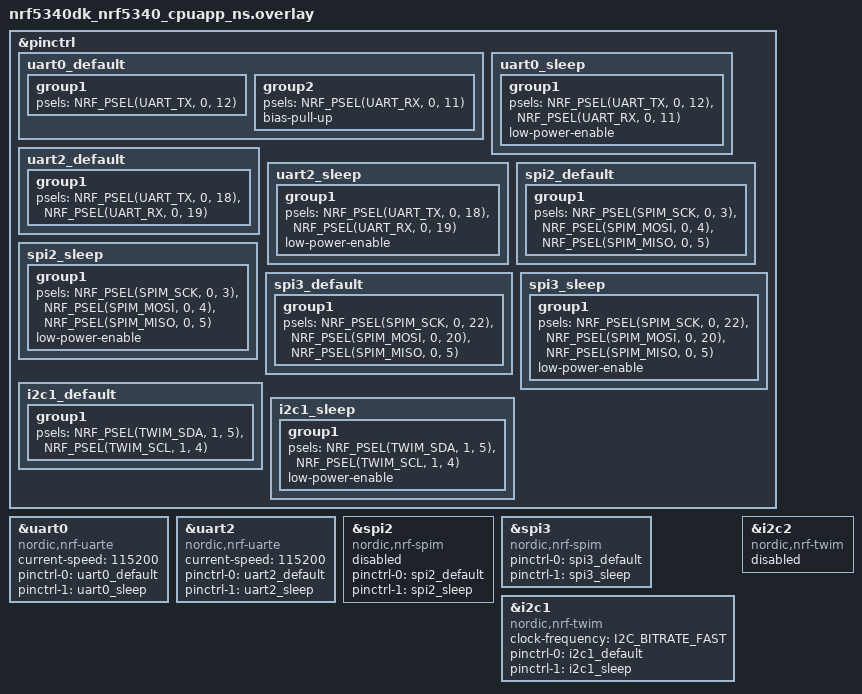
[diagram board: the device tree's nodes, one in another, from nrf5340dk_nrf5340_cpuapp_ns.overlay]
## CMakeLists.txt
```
#
# Copyright (c) 2019 Nordic Semiconductor ASA
#
# SPDX-License-Identifier: LicenseRef-BSD-5-Clause-Nordic
#

cmake_minimum_required(VERSION 3.20.0)

if (EXISTS "${CMAKE_CURRENT_SOURCE_DIR}/spm.conf")
  set(spm_CONF_FILE
    prj.conf
    ${CMAKE_CURRENT_LIST_DIR}/spm.conf
  )
endif()

if (EXISTS "${CMAKE_CURRENT_SOURCE_DIR}/mcuboot.conf")
  set(mcuboot_CONF_FILE
    prj.conf
    ${CMAKE_CURRENT_LIST_DIR}/mcuboot.conf
  )
endif()

find_package(Zephyr REQUIRED HINTS $ENV{ZEPHYR_BASE})
project(E2)
zephyr_compile_definitions(PROJECT_NAME=${PROJECT_NAME})

# NORDIC SDK APP START
target_sources(app PRIVATE src/main.c)
# NORDIC SDK APP END

# Include source directory
target_include_directories(app PRIVATE src)
target_include_directories(app PRIVATE $ENV{ZEPHYR_BASE}/subsys/fs/nvs)

# Application directories
add_subdirectory(src/datetime)
add_subdirectory(src/font)
add_subdirectory(src/image)
add_subdirectory(src/lcd)
add_subdirectory(src/key)
add_subdirectory(src/settings)
add_subdirectory(src/inner_flash)
add_subdirectory(src/external_flash)
add_subdirectory(src/uart_ble)
add_subdirectory(src/screen)
add_subdirectory(src/pmu)
add_subdirectory(src/codetrans)
add_subdirectory(src/communicate)
add_subdirectory(src/ucs2)
add_subdirectory(src/logger)

add_subdirectory_ifdef(CONFIG_PPG_SUPPORT src/ppg)
add_subdirectory_ifdef(CONFIG_WATCHDOG src/watchdog)
add_subdirectory_ifdef(CONFIG_FACTORY_TEST_SUPPORT src/factory_test)
```

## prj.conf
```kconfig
#
# Copyright (c) 2022 Nordic Semiconductor ASA
#
# SPDX-License-Identifier: LicenseRef-Nordic-5-Clause
#
# General config
CONFIG_NEWLIB_LIBC=y
CONFIG_NEWLIB_LIBC_FLOAT_PRINTF=y
CONFIG_ASSERT=y
CONFIG_REBOOT=y
CONFIG_GPIO=y
CONFIG_TRUSTED_EXECUTION_NONSECURE=y

# Log
CONFIG_LOG=y
CONFIG_USE_SEGGER_RTT=y
CONFIG_LOG_BACKEND_RTT=y
CONFIG_LOG_BACKEND_UART=n
CONFIG_LOG_DEFAULT_LEVEL=4
CONFIG_LOG_MODE_OVERFLOW=y
CONFIG_LOG_BACKEND_RTT_MODE_DROP=y
CONFIG_LOG_BACKEND_SHOW_COLOR=n
CONFIG_LOG_BACKEND_FORMAT_TIMESTAMP=n

# PinCtrl
CONFIG_PINCTRL=y
CONFIG_PINCTRL_NRF=y

# watch dog
CONFIG_WATCHDOG=y
CONFIG_WATCHDOG_TIMEOUT_MSEC=10000

# Fuel gauge
CONFIG_NRF_FUEL_GAUGE=y

# NVS
CONFIG_FLASH=y
CONFIG_FLASH_PAGE_LAYOUT=y
CONFIG_NVS=y
CONFIG_NVS_LOG_LEVEL_DBG=y
CONFIG_MPU_ALLOW_FLASH_WRITE=y

# Console
CONFIG_CONSOLE_SUBSYS=n
CONFIG_CONSOLE_HANDLER=n
CONFIG_CONSOLE_GETCHAR=n
CONFIG_CONSOLE=y
CONFIG_RTT_CONSOLE=y
CONFIG_UART_CONSOLE=n


# Library for buttons and LEDs
CONFIG_DK_LIBRARY=y

# Heap and stacks
CONFIG_HEAP_MEM_POOL_SIZE=16384
CONFIG_MAIN_STACK_SIZE=8192
CONFIG_SYSTEM_WORKQUEUE_STACK_SIZE=2048
CONFIG_HW_STACK_PROTECTION=y

# SPI
CONFIG_SPI=y

# I2C
CONFIG_I2C=y

# UART
CONFIG_SERIAL=y
CONFIG_UART_INTERRUPT_DRIVEN=y

# PPG
CONFIG_PPG_SUPPORT=y

# BLE
CONFIG_BLE_SUPPORT=n

# CRC Check
CONFIG_CRC_SUPPORT=y

# DEVICE POWER MANAGEMENT
CONFIG_PM_DEVICE=y

# Facotry test
CONFIG_FACTORY_TEST_SUPPORT=n
CONFIG_ENTROPY_GENERATOR=y
CONFIG_TEST_RANDOM_GENERATOR=y
```

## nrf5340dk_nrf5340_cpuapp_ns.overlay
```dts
/* SPDX-License-Identifier: Apache-2.0 */

&pinctrl
{
	uart0_default: uart0_default
	{
		group1
		{
			psels = <NRF_PSEL(UART_TX, 0, 12)>;
		};
		group2
		{
			psels = <NRF_PSEL(UART_RX, 0, 11)>;
			bias-pull-up;
		};
	};

	uart0_sleep: uart0_sleep
	{
		group1
		{
			psels = <NRF_PSEL(UART_TX, 0, 12)>,
							<NRF_PSEL(UART_RX, 0, 11)>;
			low-power-enable;
		};
	};
	
	uart2_default: uart2_default
	{
		group1
		{
			psels = <NRF_PSEL(UART_TX, 0, 18)>,
							<NRF_PSEL(UART_RX, 0, 19)>;
		};
	};

	uart2_sleep: uart2_sleep
	{
		group1
		{
			psels = <NRF_PSEL(UART_TX, 0, 18)>,
							<NRF_PSEL(UART_RX, 0, 19)>;
			low-power-enable;
		};
	};
	
	spi2_default: spi2_default
	{
		group1
		{
			psels = <NRF_PSEL(SPIM_SCK,  0, 3)>,
							<NRF_PSEL(SPIM_MOSI, 0, 4)>,
							<NRF_PSEL(SPIM_MISO, 0, 5)>;
		};
	};

	spi2_sleep: spi2_sleep
	{
		group1
		{
			psels = <NRF_PSEL(SPIM_SCK,  0, 3)>,
							<NRF_PSEL(SPIM_MOSI, 0, 4)>,
							<NRF_PSEL(SPIM_MISO, 0, 5)>;
			low-power-enable;
		};
	};
	
	spi3_default: spi3_default
	{
		group1
		{
			psels = <NRF_PSEL(SPIM_SCK,  0, 22)>,
							<NRF_PSEL(SPIM_MOSI, 0, 20)>,
							<NRF_PSEL(SPIM_MISO, 0, 5)>;
		};
	};

	spi3_sleep: spi3_sleep
	{
		group1
		{
			psels = <NRF_PSEL(SPIM_SCK,  0, 22)>,
							<NRF_PSEL(SPIM_MOSI, 0, 20)>,
							<NRF_PSEL(SPIM_MISO, 0, 5)>;
			low-power-enable;
		};
	};
	
	i2c1_default: i2c1_default
	{
		group1
		{
			psels = <NRF_PSEL(TWIM_SDA, 1, 5)>,
							<NRF_PSEL(TWIM_SCL, 1, 4)>;
		};
	};

	i2c1_sleep: i2c1_sleep
	{
		group1
		{
			psels = <NRF_PSEL(TWIM_SDA, 1, 5)>,
							<NRF_PSEL(TWIM_SCL, 1, 4)>;
			low-power-enable;
		};
	};
};


&uart0{
	compatible = "nordic,nrf-uarte";
	status = "okay";
	current-speed = <115200>;
	pinctrl-0 = <&uart0_default>;
	pinctrl-1 = <&uart0_sleep>;
	pinctrl-names = "default", "sleep";
};

&uart2{
	compatible = "nordic,nrf-uarte";
	status = "okay";
	current-speed = <115200>;
	pinctrl-0 = <&uart2_default>;
	pinctrl-1 = <&uart2_sleep>;
	pinctrl-names = "default", "sleep";
};

&spi2{
	compatible = "nordic,nrf-spim";
	status = "disabled";
	pinctrl-0 = <&spi2_default>;
	pinctrl-1 = <&spi2_sleep>;
	pinctrl-names = "default", "sleep";
};

&spi3{
	compatible = "nordic,nrf-spim";
	status = "okay";
	pinctrl-0 = <&spi3_default>;
	pinctrl-1 = <&spi3_sleep>;
	pinctrl-names = "default", "sleep";
};

&i2c1{
	compatible = "nordic,nrf-twim";
	status = "okay";
	clock-frequency = <I2C_BITRATE_FAST>;
	pinctrl-0 = <&i2c1_default>;
	pinctrl-1 = <&i2c1_sleep>;
	pinctrl-names = "default", "sleep";
};

&i2c2{
	compatible = "nordic,nrf-twim";
	status = "disabled";
};
```

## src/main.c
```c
/*
* Copyright (c) 2019 Nordic Semiconductor ASA
*
* SPDX-License-Identifier: LicenseRef-BSD-5-Clause-Nordic
*/

#include <zephyr/kernel.h>
#include <zephyr/device.h>
#include <stdio.h>
#include <zephyr/sys/printk.h>
#include <power/reboot.h>
#include <zephyr/drivers/spi.h>
#include <zephyr/drivers/gpio.h>
#include <dk_buttons_and_leds.h>
#include "datetime.h"
#include "inner_flash.h"
#include "external_flash.h"
#include "uart_ble.h"
#include "settings.h"
#include "pmu.h"
#include "codetrans.h"
#ifdef CONFIG_WATCHDOG
#include "watchdog.h"
#endif
#include "logger.h"

static bool sys_pwron_completed_flag = false;

static void modem_init(void)
{
	//nrf_modem_lib_init(NORMAL_MODE);
	//boot_write_img_confirmed();
}

void system_init(void)
{
	k_sleep(K_MSEC(500));//xb test 2022-03-11 启动时候延迟0.5S,等待其他外设完全启动

	modem_init();

	InitSystemSettings();

#ifdef CONFIG_PPG_SUPPORT
	//PPG_i2c_off();
#endif
	//pmu_init();
	key_init();
	//flash_init();
	
#ifdef CONFIG_PPG_SUPPORT	
	//PPG_init();
#endif
#ifdef CONFIG_ECG_SUPPORT
	ECG_init();
#endif
	//ble_init();
	//LogInit();
}

void work_init(void)
{
	if(IS_ENABLED(CONFIG_WATCHDOG))
	{
		watchdog_init_and_start(&k_sys_work_q);
	}
}

bool system_is_completed(void)
{
	return sys_pwron_completed_flag;
}

void system_init_completed(void)
{
	if(!sys_pwron_completed_flag)
		sys_pwron_completed_flag = true;
}

/***************************************************************************
* 描  述 : main函数 
* 入  参 : 无 
* 返回值 : int 类型
**************************************************************************/
int main(void)
{
	LOGD("begin");

	work_init();
	system_init();
	
//	test_show_string();
//	test_show_image();
//	test_show_color();
//	test_show_stripe();
//	test_nvs();
//	test_flash();
//	test_uart_ble();
//	test_sensor();
//	test_show_digital_clock();
//	test_sensor();
//	test_pmu();
//	test_crypto();
//	test_imei_for_qr();
//	test_tp();
//	test_gps_on();
//	test_nb();
//	test_i2c();
//	test_bat_soc();
//	test_notify();
//	test_wifi();
//	LogInit();

	while(1)
	{
		KeyMsgProcess();
		TimeMsgProcess();
		PMUMsgProcess();
	#ifdef CONFIG_PPG_SUPPORT	
		PPGMsgProcess();
	#endif
	#ifdef CONFIG_ECG_SUPPORT
		ECGMsgProcess();
	#endif
		SettingsMsgPorcess();
		UartMsgProc();
	#ifdef CONFIG_FACTORY_TEST_SUPPORT
		FactoryTestProccess();
	#endif
		LogMsgProcess();
		system_init_completed();
		k_cpu_idle();
	}
}
```
